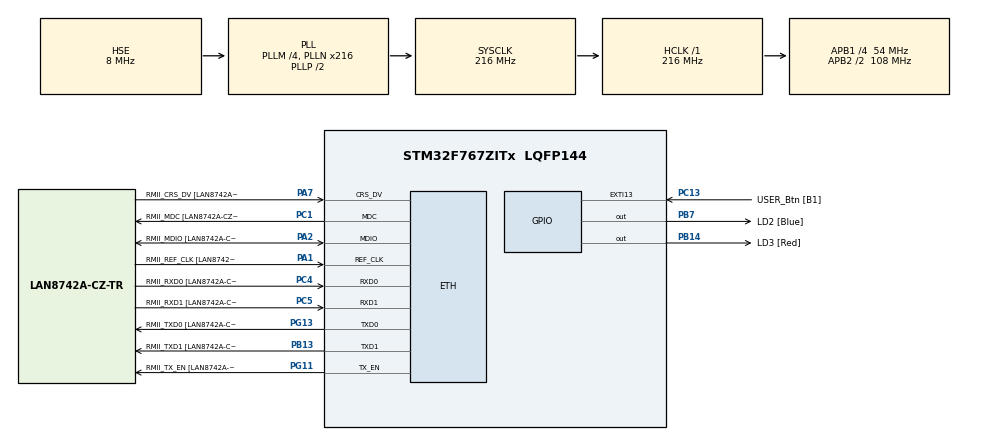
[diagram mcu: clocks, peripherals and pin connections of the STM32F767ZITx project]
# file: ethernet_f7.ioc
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CORTEX_M7.ART_ACCLERATOR_ENABLE=1
CORTEX_M7.CPU_DCache=Enabled
CORTEX_M7.CPU_ICache=Enabled
CORTEX_M7.PREFETCH_ENABLE=1
ETH.MediaInterface=ETH_MEDIA_INTERFACE_RMII
ETH.PHY_Name=LAN8742A_PHY_ADDRESS
ETH.PHY_Value=0
ETH.PhyAddress=0
FREERTOS.Tasks01=defaultTask,0,128,StartDefaultTask,Default,NULL
FREERTOS.configUSE_COUNTING_SEMAPHORES=1
FREERTOS.configUSE_RECURSIVE_MUTEXES=1
LWIP.GATEWAY_ADDRESS=192.168.002.001
LWIP.IP_ADDRESS=192.168.002.012
LWIP.LWIP_DHCP=0
LWIP.NETMASK_ADDRESS=255.255.255.000
LWIP.Version=v2.0.3_Cube
Mcu.Family=STM32F7
Mcu.Name=STM32F767ZITx
Mcu.Package=LQFP144
NVIC.ETH_IRQn=true\:5\:0\:false\:false\:true\:true\:false\:true
NVIC.PriorityGroup=NVIC_PRIORITYGROUP_4
NVIC.TIM6_DAC_IRQn=true\:0\:0\:false\:false\:true\:false\:false\:true
NVIC.TimeBase=TIM6_DAC_IRQn
NVIC.TimeBaseIP=TIM6
PA1.GPIO_Label=RMII_REF_CLK [LAN8742A-CZ-TR_REFCLK0]
PA1.Mode=RMII
PA1.Signal=ETH_REF_CLK
PA13.GPIO_Label=TMS
PA13.Mode=Serial_Wire
PA13.Signal=SYS_JTMS-SWDIO
PA14.GPIO_Label=TCK
PA14.Mode=Serial_Wire
PA14.Signal=SYS_JTCK-SWCLK
PA2.GPIO_Label=RMII_MDIO [LAN8742A-CZ-TR_MDIO]
PA2.Mode=RMII
PA2.Signal=ETH_MDIO
PA7.GPIO_Label=RMII_CRS_DV [LAN8742A-CZ-TR_CRS_DV]
PA7.Mode=RMII
PA7.Signal=ETH_CRS_DV
PB13.GPIO_Label=RMII_TXD1 [LAN8742A-CZ-TR_TXD1]
PB13.Mode=RMII
PB13.Signal=ETH_TXD1
PB14.GPIO_Label=LD3 [Red]
PB14.Signal=GPIO_Output
PB3.GPIO_Label=SWO
PB3.Signal=SYS_JTDO-SWO
PB7.GPIO_Label=LD2 [Blue]
PB7.Signal=GPIO_Output
PC1.GPIO_Label=RMII_MDC [LAN8742A-CZ-TR_MDC]
PC1.Mode=RMII
PC1.Signal=ETH_MDC
PC13.GPIO_Label=USER_Btn [B1]
PC13.Signal=GPXTI13
PC14/OSC32_IN.Mode=LSE-External-Oscillator
PC14/OSC32_IN.Signal=RCC_OSC32_IN
PC15/OSC32_OUT.Mode=LSE-External-Oscillator
PC15/OSC32_OUT.Signal=RCC_OSC32_OUT
PC4.GPIO_Label=RMII_RXD0 [LAN8742A-CZ-TR_RXD0]
PC4.Mode=RMII
PC4.Signal=ETH_RXD0
PC5.GPIO_Label=RMII_RXD1 [LAN8742A-CZ-TR_RXD1]
PC5.Mode=RMII
PC5.Signal=ETH_RXD1
PG11.GPIO_Label=RMII_TX_EN [LAN8742A-CZ-TR_TXEN]
PG11.Mode=RMII
PG11.Signal=ETH_TX_EN
PG13.GPIO_Label=RMII_TXD0 [LAN8742A-CZ-TR_TXD0]
PG13.Mode=RMII
PG13.Signal=ETH_TXD0
PH0/OSC_IN.GPIO_Label=MCO [STM32F103CBT6_PA8]
PH0/OSC_IN.Mode=HSE-External-Clock-Source
PH0/OSC_IN.Signal=RCC_OSC_IN
PH1/OSC_OUT.Mode=HSE-External-Clock-Source
PH1/OSC_OUT.Signal=RCC_OSC_OUT
ProjectManager.HeapSize=0x200
ProjectManager.StackSize=0x400
ProjectManager.TargetToolchain=STM32CubeIDE
RCC.48MHZClocksFreq_Value=24000000
RCC.AHBFreq_Value=216000000
RCC.APB1CLKDivider=RCC_HCLK_DIV4
RCC.APB1Freq_Value=54000000
RCC.APB1TimFreq_Value=108000000
RCC.APB2CLKDivider=RCC_HCLK_DIV2
RCC.APB2Freq_Value=108000000
RCC.APB2TimFreq_Value=216000000
RCC.CortexFreq_Value=216000000
RCC.HCLKFreq_Value=216000000
RCC.HSE_VALUE=8000000
RCC.HSI_VALUE=16000000
RCC.PLLM=4
RCC.PLLMUL=RCC_PLL_MUL9
RCC.PLLN=216
RCC.PLLQ=9
RCC.PLLSourceVirtual=RCC_PLLSOURCE_HSE
RCC.PRESCALERUSB=RCC_USBCLKSOURCE_PLL_DIV1_5
RCC.SYSCLKFreq_VALUE=216000000
RCC.SYSCLKSource=RCC_SYSCLKSOURCE_PLLCLK
RCC.SYSCLKSourceVirtual=RCC_SYSCLKSOURCE_PLLCLK
RCC.USBFreq_Value=48000000
RCC.VCOOutputFreq_Value=432000000
VP_FREERTOS_VS_CMSIS_V1.Mode=CMSIS_V1
VP_LWIP_VS_Enabled.Mode=Enabled
VP_SYS_VS_tim6.Mode=TIM6
board=NUCLEO-F767ZI

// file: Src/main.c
/* USER CODE BEGIN Header */
/**
 ******************************************************************************
 * @file           : main.c
 * @brief          : Main program body
 ******************************************************************************
 * @attention
 *
 * <h2><center>&copy; Copyright (c) 2019 STMicroelectronics.
 * All rights reserved.</center></h2>
 *
 * This software component is licensed by ST under BSD 3-Clause license,
 * the "License"; You may not use this file except in compliance with the
 * License. You may obtain a copy of the License at:
 *                        opensource.org/licenses/BSD-3-Clause
 *
 ******************************************************************************
 */
/* USER CODE END Header */

#include "main.h"
#include "cmsis_os.h"
#include "lwip.h"

/* USER CODE BEGIN Includes */
#include "network.h"
#include "utils.h"
/* USER CODE END Includes */

osThreadId defaultTaskHandle;

void SystemClock_Config(void);
static void MX_GPIO_Init(void);
void StartDefaultTask(void const * argument);

int main(void)
{

	/* Enable I-Cache---------------------------------------------------------*/
	SCB_EnableICache();

	/* Enable D-Cache---------------------------------------------------------*/
	SCB_EnableDCache();

	/* MCU Configuration--------------------------------------------------------*/

	/* Reset of all peripherals, Initializes the Flash interface and the Systick. */
	HAL_Init();

	/* Configure the system clock */
	SystemClock_Config();

	/* Initialize all configured peripherals */
	MX_GPIO_Init();
	/* USER CODE BEGIN 2 */
	vUtilsSetup();
	/* USER CODE END 2 */

	/* Create the thread(s) */
	/* definition and creation of defaultTask */
	osThreadDef(defaultTask, StartDefaultTask, osPriorityNormal, 0, 128);
	defaultTaskHandle = osThreadCreate(osThread(defaultTask), NULL);

	/* Start scheduler */
	osKernelStart();

	/* We should never get here as control is now taken by the scheduler */

	/* Infinite loop */
	while (1)
	{

	}
}

void SystemClock_Config(void)
{
	RCC_OscInitTypeDef RCC_OscInitStruct = {0};
	RCC_ClkInitTypeDef RCC_ClkInitStruct = {0};

	/** Configure LSE Drive Capability
	 */
	HAL_PWR_EnableBkUpAccess();
	/** Configure the main internal regulator output voltage
	 */
	__HAL_RCC_PWR_CLK_ENABLE();
	__HAL_PWR_VOLTAGESCALING_CONFIG(PWR_REGULATOR_VOLTAGE_SCALE1);
	/** Initializes the CPU, AHB and APB busses clocks
	 */
	RCC_OscInitStruct.OscillatorType = RCC_OSCILLATORTYPE_HSE;
	RCC_OscInitStruct.HSEState = RCC_HSE_BYPASS;
	RCC_OscInitStruct.PLL.PLLState = RCC_PLL_ON;
	RCC_OscInitStruct.PLL.PLLSource = RCC_PLLSOURCE_HSE;
	RCC_OscInitStruct.PLL.PLLM = 4;
	RCC_OscInitStruct.PLL.PLLN = 216;
	RCC_OscInitStruct.PLL.PLLP = RCC_PLLP_DIV2;
	RCC_OscInitStruct.PLL.PLLQ = 9;
	if (HAL_RCC_OscConfig(&RCC_OscInitStruct) != HAL_OK)
	{
		Error_Handler();
	}
	/** Activate the Over-Drive mode
	 */
	if (HAL_PWREx_EnableOverDrive() != HAL_OK)
	{
		Error_Handler();
	}
	/** Initializes the CPU, AHB and APB busses clocks
	 */
	RCC_ClkInitStruct.ClockType = RCC_CLOCKTYPE_HCLK|RCC_CLOCKTYPE_SYSCLK
			|RCC_CLOCKTYPE_PCLK1|RCC_CLOCKTYPE_PCLK2;
	RCC_ClkInitStruct.SYSCLKSource = RCC_SYSCLKSOURCE_PLLCLK;
	RCC_ClkInitStruct.AHBCLKDivider = RCC_SYSCLK_DIV1;
	RCC_ClkInitStruct.APB1CLKDivider = RCC_HCLK_DIV4;
	RCC_ClkInitStruct.APB2CLKDivider = RCC_HCLK_DIV2;

	if (HAL_RCC_ClockConfig(&RCC_ClkInitStruct, FLASH_LATENCY_7) != HAL_OK)
	{
		Error_Handler();
	}
}

static void MX_GPIO_Init(void)
{
	GPIO_InitTypeDef GPIO_InitStruct = {0};

	/* GPIO Ports Clock Enable */
	__HAL_RCC_GPIOC_CLK_ENABLE();
	__HAL_RCC_GPIOH_CLK_ENABLE();
	__HAL_RCC_GPIOA_CLK_ENABLE();
	__HAL_RCC_GPIOB_CLK_ENABLE();
	__HAL_RCC_GPIOG_CLK_ENABLE();

	/*Configure GPIO pin Output Level */
	HAL_GPIO_WritePin(GPIOB, LD3_Pin|LD2_Pin, GPIO_PIN_RESET);

	/*Configure GPIO pin : USER_Btn_Pin */
	GPIO_InitStruct.Pin = USER_Btn_Pin;
	GPIO_InitStruct.Mode = GPIO_MODE_IT_RISING;
	GPIO_InitStruct.Pull = GPIO_NOPULL;
	HAL_GPIO_Init(USER_Btn_GPIO_Port, &GPIO_InitStruct);

	/*Configure GPIO pins : LD3_Pin LD2_Pin */
	GPIO_InitStruct.Pin = LD3_Pin|LD2_Pin;
	GPIO_InitStruct.Mode = GPIO_MODE_OUTPUT_PP;
	GPIO_InitStruct.Pull = GPIO_NOPULL;
	GPIO_InitStruct.Speed = GPIO_SPEED_FREQ_LOW;
	HAL_GPIO_Init(GPIOB, &GPIO_InitStruct);

}

void StartDefaultTask(void const * argument)
{
	/* init code for LWIP */
	MX_LWIP_Init();

	/* USER CODE BEGIN 5 */
	vNetworkTcpInit();
	/* Infinite loop */
	for(;;)
	{
		osDelay(1);
	}
	/* USER CODE END 5 */
}

void HAL_TIM_PeriodElapsedCallback(TIM_HandleTypeDef *htim)
{
	if (htim->Instance == TIM6) {
		HAL_IncTick();
	}
}

void Error_Handler(void)
{
}

/************************ (C) COPYRIGHT STMicroelectronics *****END OF FILE****/
